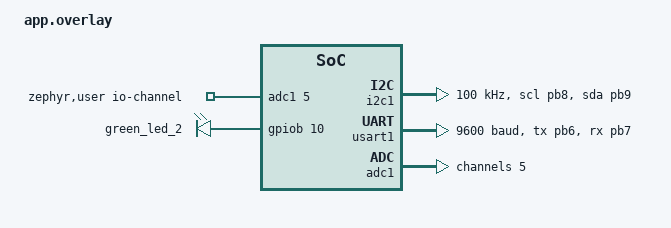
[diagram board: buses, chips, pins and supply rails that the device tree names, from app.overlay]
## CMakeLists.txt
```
cmake_minimum_required(VERSION 3.20.0)

find_package(Zephyr REQUIRED HINTS $ENV{ZEPHYR_BASE})
project(drone_telemetry)

target_sources(app PRIVATE
    src/main.c
    src/sensor_contract.c
    src/processing.c
    src/mode_manager.c
    src/simu_protocol.c
    src/output_formatter.c
)

target_include_directories(app PRIVATE include)
```

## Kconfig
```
source "Kconfig.zephyr"

menu "Drone telemetry application"

config APP_IMU_SAMPLE_HZ
    int "IMU sample rate"
    default 25
    range 1 200
    help
      Application-facing MPU6050 acquisition rate. The mandatory baseline
      freezes this value at 25 Hz.

config APP_GPS_UPDATE_PERIOD_MS
    int "GPS update period in milliseconds"
    default 1000
    range 100 60000

config APP_ENVIRONMENT_PERIOD_MS
    int "Environment update period in milliseconds"
    default 2000
    range 100 60000

config APP_SIMU_PERIOD_MS
    int "SIMU output period in milliseconds"
    default 100
    range 10 1000

config APP_TEST_PERIOD_MS
    int "TEST output period in milliseconds"
    default 2000
    range 100 60000

config APP_NORMAL_PERIOD_MS
    int "NORMAL output period in milliseconds"
    default 5000
    range 100 60000

config APP_MODE_BUTTON_DEBOUNCE_MS
    int "B1 button debounce interval in milliseconds"
    default 200
    range 0 5000

config APP_REPORT_BUFFER_SIZE
    int "TEST/NORMAL report buffer size"
    default 1536
    range 512 4096

config APP_ENABLE_ADVANCED_MODE
    bool "Enable the reserved ADVANCED MODE transition"
    default n
    help
      Keep disabled until the intermediate assessment grants access and the
      instructors assign an advanced requirement.

config APP_USE_MOCK_SENSORS
    bool "Use deterministic mock sensor data"
    default n
    help
      Keep the application testable before the hardware is connected. Set to
      n when the real sensor backends are ready.

config APP_LDR_DARK_RAW
    int "LDR dark calibration ADC value"
    default 150
    range 0 65535

config APP_LDR_MAX_RAW
    int "LDR maximum-light calibration ADC value"
    default 3600
    range 1 65535

config APP_IMU_CALIBRATION_MS
    int "Start-up IMU still-calibration window in milliseconds"
    default 2000
    range 0 10000
    help
      The board must be still and level for this long after boot. The mean
      gyroscope output is used as the gyro bias and the mean |a| as the
      gravity reference of the state detector and gravity compensation.
      Movement or tilt restarts the window; after five windows the calibration
      gives up and uses zero bias and 9.80665 m/s2. FLAGS bit 5 is set while
      pending. 0 disables the calibration.

# Tracker state thresholds. These defaults are the single source of truth
# (do not override them in prj.conf). They assume the start-up calibration
# above (bias-free gyro, measured gravity) and the MPU6050 10 Hz DLPF, and
# must be confirmed with a still/moving capture on the real hardware.

config APP_IDLE_ACCEL_TOLERANCE_MILLI_MPS2
    int "IDLE acceleration tolerance in milli-m/s2"
    default 400
    range 1 10000
    help
      Maximum | |a| - g_cal | for the tracker to be considered stationary.

config APP_IDLE_GYRO_THRESHOLD_DPS
    int "IDLE gyro magnitude threshold in deg/s"
    default 4
    range 1 360
    help
      Maximum bias-corrected angular velocity magnitude for IDLE.

config APP_FLYING_ACCEL_THRESHOLD_MILLI_MPS2
    int "FLYING dynamic acceleration threshold in milli-m/s2"
    default 1000
    range 1 10000
    help
      Minimum | |a| - g_cal | indicating motion. Must exceed the IDLE
      tolerance; the band in between holds the current state (hysteresis).

config APP_FLYING_GYRO_THRESHOLD_DPS
    int "FLYING gyro magnitude threshold in deg/s"
    default 10
    range 1 360
    help
      Minimum bias-corrected angular velocity magnitude indicating motion.
      Must exceed the IDLE gyro threshold.

config APP_FLYING_TILT_DEG
    int "FLYING tilt threshold in degrees"
    default 15
    range 1 89
    help
      Tilt of the sensor Z axis from vertical (sensor mounted Z-up). A
      multirotor tilts to produce horizontal thrust, so a sustained tilt
      above this value is treated as flight even if |a| stays close to g.

config APP_PROBLEM_TILT_DEG
    int "PROBLEM tilt threshold in degrees"
    default 60
    range 2 180
    help
      Tilt above this value (including an inverted tracker) is treated as a
      tip-over / crash-like event: PROBLEM state and FLAGS bit 4 once it has
      persisted for APP_PROBLEM_PERSISTENCE_MS.

config APP_IDLE_PERSISTENCE_MS
    int "IDLE persistence time in milliseconds"
    default 500
    range 0 60000

config APP_FLYING_PERSISTENCE_MS
    int "FLYING persistence time in milliseconds"
    default 300
    range 0 60000
    help
      Long enough (about 8 IMU samples) to reject a single tap or bump.

config APP_PROBLEM_PERSISTENCE_MS
    int "PROBLEM persistence time in milliseconds"
    default 1000
    range 0 60000

endmenu
```

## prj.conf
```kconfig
CONFIG_GPIO=y
CONFIG_I2C=y
CONFIG_SERIAL=y
# GPS RX (USART1) and the VCOM TX (LPUART1) are interrupt driven, so no
# thread busy-waits on a UART and the idle thread can enter WFI.
CONFIG_UART_INTERRUPT_DRIVEN=y
CONFIG_ADC=y
CONFIG_PRINTK=y
CONFIG_BOOT_BANNER=n
# Development aid only. Set to n for the final delivery build: a failed
# assertion prints on the VCOM stream and would corrupt SIMU output (GR5).
CONFIG_ASSERT=y
# Keep comfortable headroom with hardware MPU stack guards enabled.
CONFIG_MAIN_STACK_SIZE=2048
CONFIG_ISR_STACK_SIZE=2048
CONFIG_SYSTEM_WORKQUEUE_STACK_SIZE=2048
# Tracker thresholds are defined only in Kconfig (single source of truth).
```

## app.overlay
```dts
/*
 * NUCLEO-WL55JC1 hardware overlay for the Drone Tracking and Telemetry system.
 *
 * Pin mapping:
 * - I2C1 (MPU6050 @ 0x68, Si7021 @ 0x40): SCL = PB8 (CN10-27), SDA = PB9 (CN10-26)
 * - USART1 (GPS PA6H @ 9600 8N1): TX = PB6 (CN10-35), RX = PB7 (CN10-37)
 * - ADC1 IN5 (LDR divider): PB1 / A0 (CN7-28)
 * - RGB LED (Common Cathode, ACTIVE_HIGH): R = PB11 (CN10-30), G = PB10 (CN10-25), B = PB15 (CN10-28)
 * - B1 mode button (sw0): PA0
 */

#include <zephyr/dt-bindings/adc/adc.h>
#include <zephyr/dt-bindings/gpio/gpio.h>
#include <zephyr/dt-bindings/i2c/i2c.h>

/ {
    telemetry_app: telemetry_app {
        status = "okay";
        imu-sample-hz = <25>;
        gps-update-period-ms = <1000>;
        environment-period-ms = <2000>;
        simu-period-ms = <100>;
    };

    zephyr,user {
        io-channels = <&adc1 5>;
    };
};

&green_led_2 {
    gpios = <&gpiob 10 GPIO_ACTIVE_HIGH>;
};

&pwm2 {
    status = "disabled";
};

&i2c1 {
    pinctrl-0 = <&i2c1_scl_pb8 &i2c1_sda_pb9>;
    pinctrl-names = "default";
    clock-frequency = <I2C_BITRATE_STANDARD>;
    status = "okay";
};

&usart1 {
    pinctrl-0 = <&usart1_tx_pb6 &usart1_rx_pb7>;
    pinctrl-names = "default";
    current-speed = <9600>;
    status = "okay";
};

&adc1 {
    #address-cells = <1>;
    #size-cells = <0>;
    status = "okay";

    channel@5 {
        reg = <5>;
        zephyr,gain = "ADC_GAIN_1";
        zephyr,reference = "ADC_REF_INTERNAL";
        /*
         * Longest sampling time (160.5 ADC cycles). ADC_ACQ_TIME_DEFAULT maps to
         * the shortest one (1.5 cycles), too short to charge the sampling
         * capacitor through the kilo-ohm output impedance of the LDR divider.
         */
        zephyr,acquisition-time = <ADC_ACQ_TIME_MAX>;
        zephyr,resolution = <12>;
    };
};
```

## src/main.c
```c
#include <zephyr/device.h>
#include <zephyr/devicetree.h>
#include <zephyr/drivers/gpio.h>
#include <zephyr/drivers/uart.h>
#include <zephyr/kernel.h>
#include <zephyr/sys/atomic.h>
#include <zephyr/sys/printk.h>
#include <zephyr/sys/util.h>

#include "sensor_contract.h"
#include "telemetry_snapshot.h"
#include "processing.h"
#include "mode_manager.h"
#include "simu_protocol.h"
#include "output_formatter.h"

#define APP_NODE DT_NODELABEL(telemetry_app)

#if !DT_NODE_HAS_STATUS(APP_NODE, okay)
#error "The telemetry_app Device Tree node must be enabled"
#endif

#define IMU_PERIOD_MS (1000U / CONFIG_APP_IMU_SAMPLE_HZ)
#define GPS_PERIOD_MS CONFIG_APP_GPS_UPDATE_PERIOD_MS
#define ENVIRONMENT_PERIOD_MS CONFIG_APP_ENVIRONMENT_PERIOD_MS

BUILD_ASSERT(CONFIG_APP_IMU_SAMPLE_HZ == 25,
             "The mandatory baseline uses a 25 Hz IMU rate");
BUILD_ASSERT(CONFIG_APP_SIMU_PERIOD_MS == 100,
             "The mandatory SIMU period is 100 ms");
/* The IDLE and FLYING bands must not overlap (hysteresis between them). */
BUILD_ASSERT(CONFIG_APP_FLYING_ACCEL_THRESHOLD_MILLI_MPS2 >
                 CONFIG_APP_IDLE_ACCEL_TOLERANCE_MILLI_MPS2,
             "FLYING acceleration threshold must exceed the IDLE tolerance");
BUILD_ASSERT(CONFIG_APP_FLYING_GYRO_THRESHOLD_DPS >
                 CONFIG_APP_IDLE_GYRO_THRESHOLD_DPS,
             "FLYING gyro threshold must exceed the IDLE threshold");
BUILD_ASSERT(CONFIG_APP_PROBLEM_TILT_DEG > CONFIG_APP_FLYING_TILT_DEG,
             "PROBLEM tilt must exceed the FLYING tilt");

/* Consecutive read failures before a sensor is treated as faulty. */
#define SENSOR_FAULT_STREAK 3U

K_MSGQ_DEFINE(imu_event_queue, sizeof(struct imu_event), 8, 4);
K_MSGQ_DEFINE(mode_button_queue, sizeof(uint32_t), 4, 4);
K_MUTEX_DEFINE(snapshot_mutex);
K_MUTEX_DEFINE(led_mutex);
K_TIMER_DEFINE(output_timer, NULL, NULL);

static struct telemetry_snapshot snapshot;
static atomic_t active_mode;
static atomic_t active_led;
static struct processing_engine processing_engine;
static struct mode_manager mode_manager;
static uint16_t simu_sequence;

#if DT_HAS_CHOSEN(zephyr_console)
static const struct device *const console_uart_dev =
    DEVICE_DT_GET(DT_CHOSEN(zephyr_console));

#if defined(CONFIG_UART_INTERRUPT_DRIVEN)
#define VCOM_IRQ_TX 1
/*
 * Interrupt-driven VCOM transmission: output_thread hands a buffer to the
 * UART ISR and blocks on a semaphore until the last byte has left the shift
 * register. The CPU is free (idle/WFI) while the bytes are on the wire
 * instead of spinning in uart_poll_out().
 */
static K_SEM_DEFINE(vcom_tx_done, 0, 1);
static const uint8_t *vcom_tx_data;
static size_t vcom_tx_length;
static size_t vcom_tx_offset;
static bool vcom_irq_ready;

static void vcom_uart_isr(const struct device *dev, void *user_data)
{
    ARG_UNUSED(user_data);

    while (uart_irq_update(dev) > 0 && uart_irq_is_pending(dev) > 0) {
        if (uart_irq_tx_ready(dev) <= 0) {
            break;
        }
        if (vcom_tx_offset < vcom_tx_length) {
            int sent = uart_fifo_fill(dev, &vcom_tx_data[vcom_tx_offset],
                                      (int)(vcom_tx_length - vcom_tx_offset));

            if (sent <= 0) {
                break;
            }
            vcom_tx_offset += (size_t)sent;
        } else {
            /* Transmission complete (TC) after the last byte. */
            uart_irq_tx_disable(dev);
            k_sem_give(&vcom_tx_done);
            break;
        }
    }
}
#endif
#endif

static void emit_vcom_bytes(const char *data, size_t length)
{
    if (length == 0U) {
        return;
    }
#if DT_HAS_CHOSEN(zephyr_console)
#if defined(VCOM_IRQ_TX)
    if (vcom_irq_ready) {
        /* 115200 8N1 sends ~11.5 bytes/ms; allow a generous margin. */
        k_timeout_t timeout = K_MSEC((length / 10U) + 50U);

        k_sem_reset(&vcom_tx_done);
        vcom_tx_data = (const uint8_t *)data;
        vcom_tx_length = length;
        vcom_tx_offset = 0U;
        uart_irq_tx_enable(console_uart_dev);
        if (k_sem_take(&vcom_tx_done, timeout) != 0) {
            uart_irq_tx_disable(console_uart_dev);
        }
        return;
    }
#endif
    if (device_is_ready(console_uart_dev)) {
        for (size_t i = 0U; i < length; ++i) {
            uart_poll_out(console_uart_dev, (unsigned char)data[i]);
        }
        return;
    }
#endif
    printk("%.*s", (int)length, data);
}

static void init_vcom_tx(void)
{
#if defined(VCOM_IRQ_TX)
    if (device_is_ready(console_uart_dev) &&
        uart_irq_callback_user_data_set(console_uart_dev, vcom_uart_isr,
                                        NULL) == 0) {
        uart_irq_tx_disable(console_uart_dev);
        vcom_irq_ready = true;
    }
#endif
}

#if DT_NODE_HAS_STATUS(DT_NODELABEL(red_led_3), okay)
#define LED_RED_NODE DT_NODELABEL(red_led_3)
#else
#define LED_RED_NODE DT_NODELABEL(green_led_3)
#endif

static const struct gpio_dt_spec b1_button =
    GPIO_DT_SPEC_GET(DT_ALIAS(sw0), gpios);
static const struct gpio_dt_spec led_red =
    GPIO_DT_SPEC_GET(LED_RED_NODE, gpios);
static const struct gpio_dt_spec led_green =
    GPIO_DT_SPEC_GET(DT_NODELABEL(green_led_2), gpios);
static const struct gpio_dt_spec led_blue =
    GPIO_DT_SPEC_GET(DT_NODELABEL(blue_led_1), gpios);
static struct gpio_callback b1_button_cb_data;
static atomic_t leds_ready;
static enum app_led_color applied_led_color;
static bool led_color_applied;

/*
 * Called from the processing, output and mode threads. The mutex keeps the
 * three GPIO writes of one colour together, and the GPIOs are only touched
 * when the colour actually changes.
 */
static void apply_led_color(enum app_led_color color)
{
    int r = 0;
    int g = 0;
    int b = 0;

    atomic_set(&active_led, color);
    if (atomic_get(&leds_ready) == 0) {
        return;
    }

    k_mutex_lock(&led_mutex, K_FOREVER);
    if (led_color_applied && applied_led_color == color) {
        k_mutex_unlock(&led_mutex);
        return;
    }

    switch (color) {
    case APP_LED_BLUE:
        b = 1;
        break;
    case APP_LED_GREEN:
        g = 1;
        break;
    case APP_LED_YELLOW:
        r = 1;
        g = 1;
        break;
    case APP_LED_RED:
        r = 1;
        break;
    case APP_LED_MAGENTA:
        r = 1;
        b = 1;
        break;
    case APP_LED_WHITE:
        r = 1;
        g = 1;
        b = 1;
        break;
    case APP_LED_OFF:
    default:
        break;
    }

    (void)gpio_pin_set_dt(&led_red, r);
    (void)gpio_pin_set_dt(&led_green, g);
    (void)gpio_pin_set_dt(&led_blue, b);
    applied_led_color = color;
    led_color_applied = true;
    k_mutex_unlock(&led_mutex);
}

static const struct ldr_calibration ldr_calibration = {
    .dark_raw = CONFIG_APP_LDR_DARK_RAW,
    .maximum_raw = CONFIG_APP_LDR_MAX_RAW,
};

static void publish_imu_sample(const struct imu_sample *sample)
{
    struct imu_event event = {
        .kind = IMU_EVENT_SAMPLE,
        .result = SENSOR_OK,
        .sample = *sample,
    };

    if (k_msgq_put(&imu_event_queue, &event, K_NO_WAIT) != 0) {
        k_mutex_lock(&snapshot_mutex, K_FOREVER);
        snapshot.flags |= TELEMETRY_FLAG_IMU_INVALID;
        k_mutex_unlock(&snapshot_mutex);
    }
}

static void publish_imu_fault(enum sensor_result result, uint32_t timestamp_ms)
{
    struct imu_event event = {
        .kind = IMU_EVENT_FAULT,
        .result = result,
        .sample = {.timestamp_ms = timestamp_ms},
    };

    if (k_msgq_put(&imu_event_queue, &event, K_NO_WAIT) != 0) {
        k_mutex_lock(&snapshot_mutex, K_FOREVER);
        snapshot.flags |= TELEMETRY_FLAG_IMU_INVALID;
        k_mutex_unlock(&snapshot_mutex);
    }
}

static void imu_thread(void *p1, void *p2, void *p3)
{
    ARG_UNUSED(p1);
    ARG_UNUSED(p2);
    ARG_UNUSED(p3);

    while (true) {
        struct imu_sample sample;
        uint32_t timestamp_ms = k_uptime_get_32();
#if CONFIG_APP_USE_MOCK_SENSORS
        enum sensor_result result = sensor_mock_read_imu(timestamp_ms, &sample);
#else
        enum sensor_result result = sensor_hw_read_imu(timestamp_ms, &sample);
#endif

        if (result == SENSOR_OK) {
            publish_imu_sample(&sample);
        } else {
            publish_imu_fault(result, timestamp_ms);
        }
        k_msleep(IMU_PERIOD_MS);
    }
}

static void gps_thread(void *p1, void *p2, void *p3)
{
    ARG_UNUSED(p1);
    ARG_UNUSED(p2);
    ARG_UNUSED(p3);

    while (true) {
        struct gps_sample gps;
        uint32_t timestamp_ms = k_uptime_get_32();
#if CONFIG_APP_USE_MOCK_SENSORS
        enum sensor_result result = sensor_mock_read_gps(timestamp_ms, &gps);
#else
        enum sensor_result result = sensor_hw_read_gps(timestamp_ms, &gps);
#endif

        k_mutex_lock(&snapshot_mutex, K_FOREVER);
        if (result == SENSOR_OK) {
            snapshot.gps_utc_hour = gps.utc_hour;
            snapshot.gps_utc_minute = gps.utc_minute;
            snapshot.gps_utc_second = gps.utc_second;
            snapshot.gps_fix = gps.fix_valid;
            snapshot.gps_utc_valid = gps.utc_valid;
            snapshot.gps_timestamp_ms = gps.timestamp_ms;
            if (gps.fix_valid) {
                snapshot.latitude_deg = gps.latitude_deg;
                snapshot.longitude_deg = gps.longitude_deg;
                snapshot.altitude_m = gps.altitude_m;
                snapshot.satellites = gps.satellites;
                snapshot.flags &= ~TELEMETRY_FLAG_GPS_INVALID;
            } else {
                snapshot.satellites = 0U;
                snapshot.flags |= TELEMETRY_FLAG_GPS_INVALID;
            }
        } else {
            snapshot.gps_fix = false;
            snapshot.gps_utc_valid = false;
            snapshot.satellites = 0U;
            snapshot.flags |= TELEMETRY_FLAG_GPS_INVALID;
        }
        k_mutex_unlock(&snapshot_mutex);
        k_msleep(GPS_PERIOD_MS);
    }
}

static void environment_thread(void *p1, void *p2, void *p3)
{
    uint32_t env_fail_streak = 0U;
    uint32_t ldr_fail_streak = 0U;

    ARG_UNUSED(p1);
    ARG_UNUSED(p2);
    ARG_UNUSED(p3);

    k_msleep(60);

    while (true) {
        uint32_t timestamp_ms = k_uptime_get_32();
        struct environment_sample environment;
        struct ldr_sample ldr;
        float light_percent = 0.0f;
        enum sensor_result ldr_map_result = SENSOR_INVALID;
#if CONFIG_APP_USE_MOCK_SENSORS
        enum sensor_result environment_result =
            sensor_mock_read_environment(timestamp_ms, &environment);
        enum sensor_result ldr_result =
            sensor_mock_read_ldr(timestamp_ms, &ldr);
#else
        enum sensor_result environment_result =
            sensor_hw_read_environment(timestamp_ms, &environment);
        enum sensor_result ldr_result =
            sensor_hw_read_ldr(timestamp_ms, &ldr);
#endif

        if (ldr_result == SENSOR_OK) {
            ldr_map_result = ldr_map_percent(ldr.adc_raw, timestamp_ms,
                                             &ldr_calibration, &ldr,
                                             &light_percent);
        }

        k_mutex_lock(&snapshot_mutex, K_FOREVER);
        if (environment_result == SENSOR_OK) {
            env_fail_streak = 0U;
            snapshot.temperature_c = environment.temperature_c;
            snapshot.humidity_percent = environment.humidity_percent;
            snapshot.environment_sample_seq++;
            snapshot.flags &= ~TELEMETRY_FLAG_SI7021_INVALID;
        } else {
            env_fail_streak++;
            if (env_fail_streak >= SENSOR_FAULT_STREAK) {
                snapshot.flags |= TELEMETRY_FLAG_SI7021_INVALID;
            }
        }

        if (ldr_result == SENSOR_OK && ldr_map_result == SENSOR_OK) {
            ldr_fail_streak = 0U;
            snapshot.ldr_hardware_fault = false;
            snapshot.light_percent = light_percent;
            snapshot.light_sample_seq++;
            snapshot.flags &= ~TELEMETRY_FLAG_LDR_INVALID;
        } else if (ldr_result == SENSOR_OK &&
                   ldr_map_result == SENSOR_OVERFLOW) {
            /* Out of calibrated range (not railed): report clamped 0/100 % and
             * set FLAGS bit 2, without triggering PROBLEM or polluting stats. */
            ldr_fail_streak = 0U;
            snapshot.ldr_hardware_fault = false;
            snapshot.light_percent = light_percent;
            snapshot.flags |= TELEMETRY_FLAG_LDR_INVALID;
        } else {
            /* ADC read failure or railed divider (0 / 4095): keep the last
             * value, set FLAGS bit 2, and declare PROBLEM if it persists. */
            ldr_fail_streak++;
            snapshot.flags |= TELEMETRY_FLAG_LDR_INVALID;
            if (ldr_fail_streak >= SENSOR_FAULT_STREAK) {
                snapshot.ldr_hardware_fault = true;
            }
        }
        k_mutex_unlock(&snapshot_mutex);
        k_msleep(ENVIRONMENT_PERIOD_MS);
    }
}

static void processing_thread(void *p1, void *p2, void *p3)
{
    ARG_UNUSED(p1);
    ARG_UNUSED(p2);
    ARG_UNUSED(p3);

    const struct state_detector_config detector_config = {
        .idle_acceleration_tolerance_mps2 =
            (float)CONFIG_APP_IDLE_ACCEL_TOLERANCE_MILLI_MPS2 / 1000.0f,
        .idle_gyro_threshold_dps = (float)CONFIG_APP_IDLE_GYRO_THRESHOLD_DPS,
        .flying_acceleration_threshold_mps2 =
            (float)CONFIG_APP_FLYING_ACCEL_THRESHOLD_MILLI_MPS2 / 1000.0f,
        .flying_gyro_threshold_dps = (float)CONFIG_APP_FLYING_GYRO_THRESHOLD_DPS,
        .flying_tilt_deg = (float)CONFIG_APP_FLYING_TILT_DEG,
        .problem_tilt_deg = (float)CONFIG_APP_PROBLEM_TILT_DEG,
        .idle_persistence_ms = CONFIG_APP_IDLE_PERSISTENCE_MS,
        .flying_persistence_ms = CONFIG_APP_FLYING_PERSISTENCE_MS,
        .problem_persistence_ms = CONFIG_APP_PROBLEM_PERSISTENCE_MS,
        .imu_calibration_ms = CONFIG_APP_IMU_CALIBRATION_MS,
    };

    processing_engine_init(&processing_engine, &detector_config);

    while (true) {
        struct imu_event event;

        (void)k_msgq_get(&imu_event_queue, &event, K_FOREVER);
        k_mutex_lock(&snapshot_mutex, K_FOREVER);

        snapshot.timestamp_ms = event.sample.timestamp_ms;
        if (event.kind == IMU_EVENT_SAMPLE && event.result == SENSOR_OK) {
            /* processing publishes the bias-corrected IMU values. */
            snapshot.flags &= ~TELEMETRY_FLAG_IMU_INVALID;
            processing_engine_process_imu(&processing_engine,
                                          &event.sample, &snapshot);
        } else {
            snapshot.flags |= TELEMETRY_FLAG_IMU_INVALID;
            processing_engine_process_imu_fault(&processing_engine,
                                                event.sample.timestamp_ms,
                                                &snapshot);
        }

        enum tracker_state state = snapshot.state;

        k_mutex_unlock(&snapshot_mutex);
        apply_led_color(
            mode_manager_led_for((enum app_mode)atomic_get(&active_mode),
                                 state));
    }
}

static void output_thread(void *p1, void *p2, void *p3)
{
    ARG_UNUSED(p1);
    ARG_UNUSED(p2);
    ARG_UNUSED(p3);

    while (true) {
        struct telemetry_snapshot local_snapshot;
        static enum app_mode last_output_mode = APP_MODE_TEST;
        static bool output_mode_initialized;
        static bool stats_baseline_initialized;
        static uint32_t last_stats_window_end_ms;
        static char report[CONFIG_APP_REPORT_BUFFER_SIZE];
        bool include_statistics = false;
        int report_length = 0;

        (void)k_timer_status_sync(&output_timer);
        uint32_t output_timestamp_ms = k_uptime_get_32();
        k_mutex_lock(&snapshot_mutex, K_FOREVER);
        local_snapshot = snapshot;
        k_mutex_unlock(&snapshot_mutex);
        local_snapshot.timestamp_ms = output_timestamp_ms;

        /*
         * output_thread is the only VCOM writer: it applies the mode LED
         * policy and emits the TEST, NORMAL or SIMU output for this period.
         */
        enum app_mode mode = (enum app_mode)atomic_get(&active_mode);
        enum tracker_state state = local_snapshot.state;
        apply_led_color(mode_manager_led_for(mode, state));

        if (!output_mode_initialized || mode != last_output_mode) {
            output_mode_initialized = true;
            last_output_mode = mode;
            stats_baseline_initialized = mode == APP_MODE_NORMAL;
            last_stats_window_end_ms = local_snapshot.statistics.window_end_ms;
        }

        if (mode == APP_MODE_SIMU) {
            char frame[SIMU_FRAME_BUFFER_SIZE];

            if (simu_format_frame(&local_snapshot, simu_sequence, frame) == 0) {
                emit_vcom_bytes(frame, SIMU_FRAME_LENGTH);
                simu_sequence++;
            }
        } else if (mode == APP_MODE_TEST) {
            report_length = output_format_test_report(
                &local_snapshot, report, sizeof(report));
        } else if (mode == APP_MODE_NORMAL) {
            if (local_snapshot.statistics.valid &&
                stats_baseline_initialized &&
                local_snapshot.statistics.window_end_ms !=
                    last_stats_window_end_ms) {
                include_statistics = true;
                last_stats_window_end_ms =
                    local_snapshot.statistics.window_end_ms;
            }
            report_length = output_format_normal_report(
                &local_snapshot, include_statistics,
                report, sizeof(report));
#if CONFIG_APP_ENABLE_ADVANCED_MODE
        } else if (mode == APP_MODE_ADVANCED) {
            report_length = output_format_normal_report(
                &local_snapshot, false, report, sizeof(report));
#endif
        }

        if (report_length > 0) {
            emit_vcom_bytes(report, (size_t)report_length);
        }
    }
}

/*
 * Called from the B1 GPIO interrupt (b1_button_isr). It only queues the
 * press timestamp; mode_thread performs the debounced transition and the
 * output timer update in thread context.
 */
void app_b1_button_pressed(uint32_t timestamp_ms)
{
    (void)k_msgq_put(&mode_button_queue, &timestamp_ms, K_NO_WAIT);
}

static void b1_button_isr(const struct device *dev,
                          struct gpio_callback *cb,
                          uint32_t pins)
{
    ARG_UNUSED(dev);
    ARG_UNUSED(cb);
    ARG_UNUSED(pins);
    app_b1_button_pressed(k_uptime_get_32());
}

static void init_gpio_peripherals(void)
{
    if (led_red.port != NULL && led_green.port != NULL &&
        led_blue.port != NULL &&
        gpio_is_ready_dt(&led_red) &&
        gpio_is_ready_dt(&led_green) &&
        gpio_is_ready_dt(&led_blue) &&
        gpio_pin_configure_dt(&led_red, GPIO_OUTPUT_INACTIVE) == 0 &&
        gpio_pin_configure_dt(&led_green, GPIO_OUTPUT_INACTIVE) == 0 &&
        gpio_pin_configure_dt(&led_blue, GPIO_OUTPUT_INACTIVE) == 0) {
        atomic_set(&leds_ready, 1);
    }

    if (b1_button.port != NULL &&
        gpio_is_ready_dt(&b1_button) &&
        gpio_pin_configure_dt(&b1_button, GPIO_INPUT) == 0 &&
        gpio_pin_interrupt_configure_dt(&b1_button,
                                        GPIO_INT_EDGE_TO_ACTIVE) == 0) {
        gpio_init_callback(&b1_button_cb_data, b1_button_isr,
                           BIT(b1_button.pin));
        (void)gpio_add_callback(b1_button.port, &b1_button_cb_data);
    }
}

static void mode_thread(void *p1, void *p2, void *p3)
{
    ARG_UNUSED(p1);
    ARG_UNUSED(p2);
    ARG_UNUSED(p3);

    while (true) {
        uint32_t timestamp_ms;

        (void)k_msgq_get(&mode_button_queue, &timestamp_ms, K_FOREVER);
        if (!mode_manager_accept_button(&mode_manager, timestamp_ms)) {
            continue;
        }

        mode_manager.mode = mode_manager_next_mode(mode_manager.mode);
        atomic_set(&active_mode, mode_manager.mode);
        enum tracker_state state;

        k_mutex_lock(&snapshot_mutex, K_FOREVER);
        state = snapshot.state;
        k_mutex_unlock(&snapshot_mutex);
        apply_led_color(mode_manager_led_for(mode_manager.mode, state));
        k_timer_start(&output_timer,
                      K_MSEC(mode_manager_period_ms(mode_manager.mode)),
                      K_MSEC(mode_manager_period_ms(mode_manager.mode)));
    }
}

K_THREAD_DEFINE(imu_thread_id, 1536, imu_thread, NULL, NULL, NULL, 5, 0, 0);
K_THREAD_DEFINE(gps_thread_id, 1536, gps_thread, NULL, NULL, NULL, 6, 0, 0);
K_THREAD_DEFINE(environment_thread_id, 1536, environment_thread, NULL, NULL, NULL, 7, 0, 0);
K_THREAD_DEFINE(processing_thread_id, 2048, processing_thread, NULL, NULL, NULL, 4, 0, 0);
K_THREAD_DEFINE(output_thread_id, 2048, output_thread, NULL, NULL, NULL, 8, 0, 0);
K_THREAD_DEFINE(mode_thread_id, 1024, mode_thread, NULL, NULL, NULL, 9, 0, 0);

int main(void)
{
    init_vcom_tx();
    init_gpio_peripherals();
    mode_manager_init(&mode_manager, CONFIG_APP_MODE_BUTTON_DEBOUNCE_MS);
    atomic_set(&active_mode, mode_manager.mode);
    apply_led_color(
        mode_manager_led_for(mode_manager.mode, TRACKER_STATE_IDLE));
    snapshot.state = TRACKER_STATE_IDLE;
    snapshot.flags = TELEMETRY_FLAG_YAW_UNRELIABLE |
                     TELEMETRY_FLAG_GPS_INVALID |
                     TELEMETRY_FLAG_LDR_INVALID |
                     TELEMETRY_FLAG_SI7021_INVALID |
                     TELEMETRY_FLAG_INERTIAL_ONLY;
    if (CONFIG_APP_IMU_CALIBRATION_MS > 0) {
        snapshot.flags |= TELEMETRY_FLAG_CALIBRATION_PENDING;
    }
    k_timer_start(&output_timer,
                  K_MSEC(mode_manager_period_ms(mode_manager.mode)),
                  K_MSEC(mode_manager_period_ms(mode_manager.mode)));

    return 0;
}
```

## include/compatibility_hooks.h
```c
#ifndef COMPATIBILITY_HOOKS_H
#define COMPATIBILITY_HOOKS_H

int config_mandatory_printf(void);
int print_alarm_messages(void);
void print_academic_integrity_marker(void);

#endif /* COMPATIBILITY_HOOKS_H */
```

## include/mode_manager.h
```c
#ifndef MODE_MANAGER_H
#define MODE_MANAGER_H

#include <stdbool.h>
#include <stdint.h>

#include "telemetry_snapshot.h"

/* The mode order is part of the mandatory B1 behaviour. */
enum app_mode {
    APP_MODE_TEST = 0,
    APP_MODE_NORMAL,
    APP_MODE_SIMU,
#if CONFIG_APP_ENABLE_ADVANCED_MODE
    APP_MODE_ADVANCED,
#endif
};

enum app_led_color {
    APP_LED_OFF = 0,
    APP_LED_BLUE,
    APP_LED_GREEN,
    APP_LED_YELLOW,
    APP_LED_RED,
    APP_LED_MAGENTA,
    APP_LED_WHITE,
};

struct mode_manager {
    enum app_mode mode;
    uint32_t button_debounce_ms;
    uint32_t last_button_ms;
    bool button_timestamp_valid;
};

void mode_manager_init(struct mode_manager *manager,
                       uint32_t button_debounce_ms);

/* Called by the B1 GPIO interrupt callback; queues the press timestamp. */
void app_b1_button_pressed(uint32_t timestamp_ms);

/* Returns true only when the press is outside the debounce interval. */
bool mode_manager_accept_button(struct mode_manager *manager,
                                uint32_t timestamp_ms);

enum app_mode mode_manager_next_mode(enum app_mode mode);
uint32_t mode_manager_period_ms(enum app_mode mode);
enum app_led_color mode_manager_led_for(enum app_mode mode,
                                        enum tracker_state state);
const char *mode_manager_name(enum app_mode mode);
const char *mode_manager_led_name(enum app_led_color color);

#endif /* MODE_MANAGER_H */
```

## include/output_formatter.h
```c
#ifndef OUTPUT_FORMATTER_H
#define OUTPUT_FORMATTER_H

#include <stdbool.h>
#include <stddef.h>

#include "telemetry_snapshot.h"

int output_format_test_report(const struct telemetry_snapshot *snapshot,
                              char *output, size_t capacity);

int output_format_normal_report(const struct telemetry_snapshot *snapshot,
                                bool include_statistics,
                                char *output, size_t capacity);

#endif /* OUTPUT_FORMATTER_H */
```

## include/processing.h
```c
#ifndef PROCESSING_H
#define PROCESSING_H

#include <stdbool.h>
#include <stdint.h>

#include "telemetry_snapshot.h"

struct attitude_state {
    uint32_t last_timestamp_ms;
    float roll_deg;
    float pitch_deg;
    float yaw_deg;
    bool initialized;
};

struct position_state {
    bool origin_valid;
    bool integration_origin_valid;
    double origin_latitude_deg;
    double origin_longitude_deg;
    float origin_altitude_m;
    uint32_t last_gps_timestamp_ms;
    bool last_gps_valid;
    double last_gps_latitude_deg;
    double last_gps_longitude_deg;
    float last_gps_altitude_m;
    float x_m;
    float y_m;
    float z_m;
    float vx_mps;
    float vy_mps;
    float vz_mps;
    uint32_t last_imu_timestamp_ms;
    bool last_imu_valid;
};

struct statistics_state {
    uint32_t window_start_ms;
    uint32_t valid_counts[5];
    float sums[5];
    float minima[5];
    float maxima[5];
    /* Last sensor sample sequence numbers already accumulated. */
    uint32_t last_light_seq;
    uint32_t last_environment_seq;
    bool initialized;
};

/*
 * Start-up IMU calibration. While the board is still, the gyroscope bias and
 * the measured gravity magnitude are averaged. Attitude and inertial position
 * are not integrated until the calibration finishes (FLAGS bit 5 is set).
 */
struct imu_calibration {
    uint32_t duration_ms;
    uint32_t first_start_ms;
    uint32_t window_start_ms;
    uint32_t samples;
    float sum_gx;
    float sum_gy;
    float sum_gz;
    float sum_accel_magnitude;
    float min_accel_magnitude;
    float max_accel_magnitude;
    float gyro_bias_x_dps;
    float gyro_bias_y_dps;
    float gyro_bias_z_dps;
    float gravity_mps2;
    bool active;
    bool done;
};

struct state_detector_config {
    float idle_acceleration_tolerance_mps2;
    float idle_gyro_threshold_dps;
    float flying_acceleration_threshold_mps2;
    float flying_gyro_threshold_dps;
    /* Tilt from the Z-up mounting: FLYING above the first, PROBLEM above the second. */
    float flying_tilt_deg;
    float problem_tilt_deg;
    uint32_t idle_persistence_ms;
    uint32_t flying_persistence_ms;
    uint32_t problem_persistence_ms;
    /* Start-up still-calibration window; 0 disables the calibration. */
    uint32_t imu_calibration_ms;
};

struct state_detector {
    enum tracker_state state;
    enum tracker_state candidate_state;
    uint32_t candidate_since_ms;
    bool candidate_valid;
};

struct processing_engine {
    struct attitude_state attitude;
    struct position_state position;
    struct statistics_state statistics;
    struct state_detector detector;
    struct state_detector_config detector_config;
    struct imu_calibration calibration;
    float cos_flying_tilt;
    float cos_problem_tilt;
};

void processing_engine_init(struct processing_engine *engine,
                            const struct state_detector_config *config);

void processing_engine_process_imu(struct processing_engine *engine,
                                   const struct imu_sample *sample,
                                   struct telemetry_snapshot *snapshot);

void processing_engine_process_imu_fault(struct processing_engine *engine,
                                         uint32_t timestamp_ms,
                                         struct telemetry_snapshot *snapshot);

#endif /* PROCESSING_H */
```

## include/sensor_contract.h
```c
#ifndef SENSOR_CONTRACT_H
#define SENSOR_CONTRACT_H

#include <stdbool.h>
#include <stddef.h>
#include <stdint.h>

#include "telemetry_snapshot.h"

#define MPU6050_ACCEL_LSB_PER_G 16384.0f
#define MPU6050_GYRO_LSB_PER_DPS 131.0f
#define MPU6050_STANDARD_GRAVITY 9.80665f

struct mpu6050_raw_sample {
    int16_t accel_x;
    int16_t accel_y;
    int16_t accel_z;
    int16_t gyro_x;
    int16_t gyro_y;
    int16_t gyro_z;
};

struct si7021_raw_sample {
    uint16_t temperature_raw;
    uint16_t humidity_raw;
};

struct ldr_calibration {
    uint16_t dark_raw;
    uint16_t maximum_raw;
};

enum sensor_result mpu6050_convert_raw(const struct mpu6050_raw_sample *raw,
                                        uint32_t timestamp_ms,
                                        struct imu_sample *out);

enum sensor_result si7021_convert_raw(const struct si7021_raw_sample *raw,
                                      uint32_t timestamp_ms,
                                      struct environment_sample *out);

/*
 * Map a raw LDR ADC sample to 0.0-100.0 %.
 * SENSOR_OK:       inside the calibrated [dark_raw, maximum_raw] range.
 * SENSOR_OVERFLOW: outside the calibrated range (1..dark_raw-1 or
 *                  maximum_raw+1..4094); *light_percent holds the clamped
 *                  0 % or 100 % value and the caller sets FLAGS bit 2.
 * SENSOR_INVALID:  invalid arguments/calibration or ADC rail (0 / >=4095,
 *                  indicating an open or shorted divider; no value produced).
 */
enum sensor_result ldr_map_percent(uint16_t adc_raw,
                                   uint32_t timestamp_ms,
                                   const struct ldr_calibration *calibration,
                                   struct ldr_sample *out,
                                   float *light_percent);

enum sensor_result gps_parse_gga(const char *line, struct gps_sample *out);

enum sensor_result sensor_mock_read_imu(uint32_t timestamp_ms,
                                        struct imu_sample *out);
enum sensor_result sensor_mock_read_gps(uint32_t timestamp_ms,
                                        struct gps_sample *out);
enum sensor_result sensor_mock_read_environment(uint32_t timestamp_ms,
                                                struct environment_sample *out);
enum sensor_result sensor_mock_read_ldr(uint32_t timestamp_ms,
                                        struct ldr_sample *out);

enum sensor_result sensor_hw_read_imu(uint32_t timestamp_ms,
                                      struct imu_sample *out);
enum sensor_result sensor_hw_read_gps(uint32_t timestamp_ms,
                                      struct gps_sample *out);
enum sensor_result sensor_hw_read_environment(uint32_t timestamp_ms,
                                              struct environment_sample *out);
enum sensor_result sensor_hw_read_ldr(uint32_t timestamp_ms,
                                      struct ldr_sample *out);

#endif /* SENSOR_CONTRACT_H */
```

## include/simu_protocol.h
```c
#ifndef SIMU_PROTOCOL_H
#define SIMU_PROTOCOL_H

#include <stddef.h>
#include <stdint.h>

#include "telemetry_snapshot.h"

/* 221 printable/terminator bytes plus the C string terminator. */
#define SIMU_FRAME_LENGTH 221U
#define SIMU_FRAME_BUFFER_SIZE (SIMU_FRAME_LENGTH + 1U)

/*
 * Format one complete SIMU frame. The sequence is five decimal digits and
 * wraps naturally at 65535. On success, output contains exactly 221 bytes,
 * including the final CRLF, followed by a NUL terminator.
 */
int simu_format_frame(const struct telemetry_snapshot *snapshot,
                      uint16_t sequence,
                      char output[SIMU_FRAME_BUFFER_SIZE]);

uint8_t simu_checksum(const char *begin, size_t length);

#endif /* SIMU_PROTOCOL_H */
```

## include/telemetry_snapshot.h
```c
#ifndef TELEMETRY_SNAPSHOT_H
#define TELEMETRY_SNAPSHOT_H

#include <stdbool.h>
#include <stdint.h>

enum tracker_state {
    TRACKER_STATE_IDLE = 0,
    TRACKER_STATE_FLYING,
    TRACKER_STATE_PROBLEM,
};

enum sensor_result {
    SENSOR_OK = 0,
    SENSOR_NOT_READY,
    SENSOR_NO_DATA,
    SENSOR_INVALID,
    SENSOR_BUS_ERROR,
    SENSOR_TIMEOUT,
    SENSOR_OVERFLOW,
    SENSOR_CONFIG_ERROR,
};

enum telemetry_flag {
    TELEMETRY_FLAG_IMU_INVALID = 0x0001,
    TELEMETRY_FLAG_GPS_INVALID = 0x0002,
    TELEMETRY_FLAG_LDR_INVALID = 0x0004,
    TELEMETRY_FLAG_SI7021_INVALID = 0x0008,
    TELEMETRY_FLAG_IMPACT = 0x0010,
    TELEMETRY_FLAG_CALIBRATION_PENDING = 0x0020,
    TELEMETRY_FLAG_INERTIAL_ONLY = 0x0040,
    TELEMETRY_FLAG_YAW_UNRELIABLE = 0x0080,
};

enum imu_event_kind {
    IMU_EVENT_SAMPLE = 0,
    IMU_EVENT_FAULT,
};

struct imu_sample {
    uint32_t timestamp_ms;
    float ax_mps2;
    float ay_mps2;
    float az_mps2;
    float gx_dps;
    float gy_dps;
    float gz_dps;
};

struct gps_sample {
    uint32_t timestamp_ms;
    double latitude_deg;
    double longitude_deg;
    float altitude_m;
    uint8_t satellites;
    uint8_t utc_hour;
    uint8_t utc_minute;
    uint8_t utc_second;
    bool fix_valid;
    bool utc_valid;
};

struct environment_sample {
    uint32_t timestamp_ms;
    float temperature_c;
    float humidity_percent;
};

struct ldr_sample {
    uint32_t timestamp_ms;
    uint16_t adc_raw;
};

struct imu_event {
    enum imu_event_kind kind;
    enum sensor_result result;
    struct imu_sample sample;
};

struct telemetry_statistics {
    uint32_t window_end_ms;
    /*
     * Per-channel sample counts for the completed window. A channel with a
     * zero count has no valid data in the window and its mean/min/max are
     * meaningless; the other channels are still reported.
     */
    uint32_t imu_samples;
    uint32_t light_samples;
    uint32_t environment_samples;
    float light_mean;
    float light_min;
    float light_max;
    float temperature_mean;
    float temperature_min;
    float temperature_max;
    float humidity_mean;
    float humidity_min;
    float humidity_max;
    float acceleration_mean;
    float acceleration_min;
    float acceleration_max;
    float angular_velocity_mean;
    float angular_velocity_min;
    float angular_velocity_max;
    bool valid;
};

struct telemetry_snapshot {
    uint32_t timestamp_ms;

    float ax_mps2;
    float ay_mps2;
    float az_mps2;
    float gx_dps;
    float gy_dps;
    float gz_dps;

    float roll_deg;
    float pitch_deg;
    float yaw_deg;

    double latitude_deg;
    double longitude_deg;
    float altitude_m;
    uint32_t gps_timestamp_ms;
    uint8_t satellites;
    uint8_t gps_utc_hour;
    uint8_t gps_utc_minute;
    uint8_t gps_utc_second;
    bool gps_fix;
    bool gps_utc_valid;

    float light_percent;
    float temperature_c;
    float humidity_percent;
    /* Incremented on every fresh measurement; used by the 30 s statistics. */
    uint32_t light_sample_seq;
    uint32_t environment_sample_seq;
    /*
     * Persistent LDR ADC failure or open/shorted divider rail (0 / 4095).
     * Unlike an out-of-calibration reading (FLAGS bit 2 only), this is a
     * device fault and counts towards the PROBLEM state.
     */
    bool ldr_hardware_fault;

    bool local_origin_valid;
    float x_m;
    float y_m;
    float z_m;
    float vx_mps;
    float vy_mps;
    float vz_mps;

    enum tracker_state state;
    uint16_t flags;
    struct telemetry_statistics statistics;
};

#endif /* TELEMETRY_SNAPSHOT_H */
```

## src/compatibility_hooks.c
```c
#include <zephyr/sys/printk.h>

#include "compatibility_hooks.h"

#if defined(__GNUC__) && (__GNUC__ >= 11)
#define APP_COMPATIBILITY_KEEP __attribute__((used, retain))
#else
#define APP_COMPATIBILITY_KEEP __attribute__((used))
#endif

APP_COMPATIBILITY_KEEP int config_mandatory_printf(void)
{
    return 2026;
}

APP_COMPATIBILITY_KEEP int print_alarm_messages(void)
{
    printk("this is an alarm\r\n");
    return 155;
}

APP_COMPATIBILITY_KEEP void print_academic_integrity_marker(void)
{
    printk("Academic-integrity marker: EP-MUIOT-2026-ORION.\r\n");
}
```

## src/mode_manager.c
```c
#include "mode_manager.h"

static bool elapsed_at_least(uint32_t now_ms, uint32_t then_ms,
                             uint32_t interval_ms)
{
    return (uint32_t)(now_ms - then_ms) >= interval_ms;
}

void mode_manager_init(struct mode_manager *manager,
                       uint32_t button_debounce_ms)
{
    manager->mode = APP_MODE_TEST;
    manager->button_debounce_ms = button_debounce_ms;
    manager->last_button_ms = 0U;
    manager->button_timestamp_valid = false;
}

bool mode_manager_accept_button(struct mode_manager *manager,
                                uint32_t timestamp_ms)
{
    if (manager->button_timestamp_valid &&
        !elapsed_at_least(timestamp_ms, manager->last_button_ms,
                          manager->button_debounce_ms)) {
        return false;
    }

    manager->last_button_ms = timestamp_ms;
    manager->button_timestamp_valid = true;
    return true;
}

enum app_mode mode_manager_next_mode(enum app_mode mode)
{
    switch (mode) {
    case APP_MODE_TEST:
        return APP_MODE_NORMAL;
    case APP_MODE_NORMAL:
        return APP_MODE_SIMU;
    case APP_MODE_SIMU:
#if CONFIG_APP_ENABLE_ADVANCED_MODE
        return APP_MODE_ADVANCED;
#else
        return APP_MODE_TEST;
#endif
#if CONFIG_APP_ENABLE_ADVANCED_MODE
    case APP_MODE_ADVANCED:
        return APP_MODE_TEST;
#endif
    default:
        return APP_MODE_TEST;
    }
}

uint32_t mode_manager_period_ms(enum app_mode mode)
{
    switch (mode) {
    case APP_MODE_TEST:
        return CONFIG_APP_TEST_PERIOD_MS;
    case APP_MODE_NORMAL:
        return CONFIG_APP_NORMAL_PERIOD_MS;
    case APP_MODE_SIMU:
        return CONFIG_APP_SIMU_PERIOD_MS;
#if CONFIG_APP_ENABLE_ADVANCED_MODE
    case APP_MODE_ADVANCED:
        return CONFIG_APP_NORMAL_PERIOD_MS;
#endif
    default:
        return CONFIG_APP_TEST_PERIOD_MS;
    }
}

enum app_led_color mode_manager_led_for(enum app_mode mode,
                                        enum tracker_state state)
{
    switch (mode) {
    case APP_MODE_TEST:
        return APP_LED_BLUE;
    case APP_MODE_SIMU:
        /* SIMU indication is independent of the tracker state. */
        return APP_LED_MAGENTA;
    case APP_MODE_NORMAL:
        switch (state) {
        case TRACKER_STATE_IDLE:
            return APP_LED_GREEN;
        case TRACKER_STATE_FLYING:
            return APP_LED_YELLOW;
        case TRACKER_STATE_PROBLEM:
            return APP_LED_RED;
        default:
            return APP_LED_RED;
        }
#if CONFIG_APP_ENABLE_ADVANCED_MODE
    case APP_MODE_ADVANCED:
        return APP_LED_WHITE;
#endif
    default:
        return APP_LED_OFF;
    }
}

const char *mode_manager_name(enum app_mode mode)
{
    switch (mode) {
    case APP_MODE_TEST:
        return "TEST";
    case APP_MODE_NORMAL:
        return "NORMAL";
    case APP_MODE_SIMU:
        return "SIMU";
#if CONFIG_APP_ENABLE_ADVANCED_MODE
    case APP_MODE_ADVANCED:
        return "ADVANCED";
#endif
    default:
        return "UNKNOWN";
    }
}

const char *mode_manager_led_name(enum app_led_color color)
{
    switch (color) {
    case APP_LED_OFF:
        return "OFF";
    case APP_LED_BLUE:
        return "BLUE";
    case APP_LED_GREEN:
        return "GREEN";
    case APP_LED_YELLOW:
        return "YELLOW";
    case APP_LED_RED:
        return "RED";
    case APP_LED_MAGENTA:
        return "MAGENTA";
    case APP_LED_WHITE:
        return "WHITE";
    default:
        return "UNKNOWN";
    }
}
```
